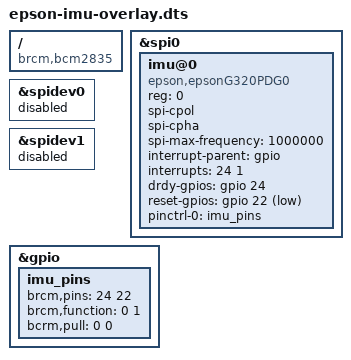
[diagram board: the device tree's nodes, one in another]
/*
* epsonImu-overlay.dts
*
* EpsonImu (inertial measurement unit) connected to spi0 on Raspberry Pi
*
*/
/dts-v1/;
/plugin/;

/ {

	compatible = "brcm,bcm2835";

        fragment@0 {
                target = <&spi0>;
                __overlay__ {
                        status = "okay";
                };
        };

        fragment@1 {
                target = <&spidev0>;
                __overlay__ {
                        status = "disabled";
                };
        };

        fragment@2 {
                target = <&spidev1>;
                __overlay__ {
                        status = "disabled";
                };
        };
	
	/* the interrupt pin of the Imu device */
	fragment@3 {
		target = <&gpio>;
		__overlay__ {
			imu_pins: imu_pins {
				brcm,pins = <24 22>;
				brcm,function = <0 1>; /* input output */
				bcrm,pull = <0 0>; /* disable pull-up */
			};
		};
	};

	fragment@4 {
		target = <&spi0>;
		__overlay__ {
			/* needed to avoid dtc warning */
			#address-cells = <1>;
			#size-cells = <0>;

			imu@0 {
				compatible = "epson,epsonG320PDG0","epson,epsonG325PDF0","epson,epsonG354PDH0","epson,epsonG365PDF0";
				reg = <0>;
				spi-cpol;
				spi-cpha;
				spi-max-frequency = <1000000>;
				interrupt-parent = <&gpio>;
				interrupts = <24 1>; /* IRQ_TYPE_EDGE_RISING */
				drdy-gpios = <&gpio 24 0>;
				reset-gpios = <&gpio 22 1>;
				/* epson-proto; */
				pinctrl-names = "default";
				pinctrl-0 = <&imu_pins>;

			};
		};
	};
};
